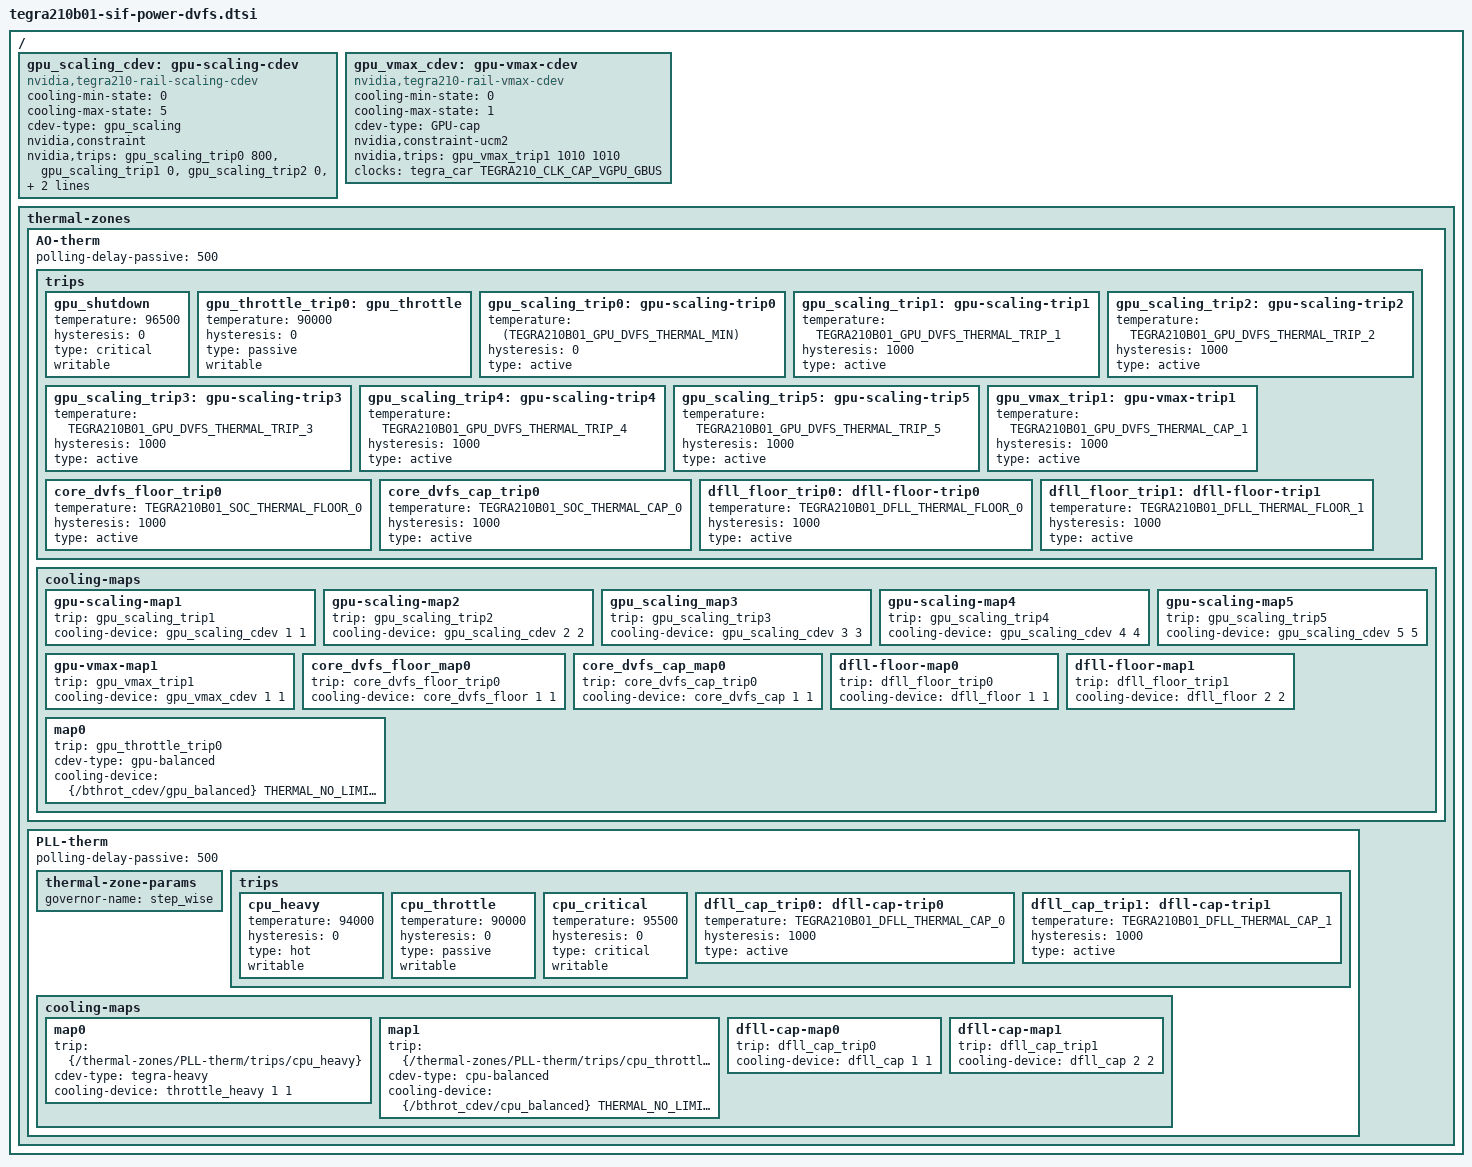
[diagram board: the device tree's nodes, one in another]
/*
 * Copyright (c) 2018, NVIDIA CORPORATION. All rights reserved.
 *
 * This software is licensed under the terms of the GNU General Public
 * License version 2, as published by the Free Software Foundation, and
 * may be copied, distributed, and modified under those terms.
 *
 * This program is distributed in the hope that it will be useful,
 * but WITHOUT ANY WARRANTY; without even the implied warranty of
 * MERCHANTABILITY or FITNESS FOR A PARTICULAR PURPOSE.  See the
 * GNU General Public License for more details.
 *
 */

#include <dt-bindings/thermal/tegra210b01-trips.h>

/ {
	gpu_scaling_cdev: gpu-scaling-cdev {
		cooling-min-state = <0>;
		cooling-max-state = <5>;
		#cooling-cells = <2>;
		compatible = "nvidia,tegra210-rail-scaling-cdev";
		cdev-type = "gpu_scaling";
		nvidia,constraint;
		nvidia,trips = <&gpu_scaling_trip0 800 &gpu_scaling_trip1 0
				&gpu_scaling_trip2 0 &gpu_scaling_trip3 0
				&gpu_scaling_trip4 0 &gpu_scaling_trip5 0>;
	};

	gpu_vmax_cdev: gpu-vmax-cdev {
		cooling-min-state = <0>;
		cooling-max-state = <1>;
		#cooling-cells = <2>;
		compatible = "nvidia,tegra210-rail-vmax-cdev";
		cdev-type = "GPU-cap";
		nvidia,constraint-ucm2;
		nvidia,trips = <&gpu_vmax_trip1 1010 1010>;
		clocks = <&tegra_car TEGRA210_CLK_CAP_VGPU_GBUS>;
		clock-names = "cap-clk";
	};

	thermal-zones {
		AO-therm {
			status = "okay";
			polling-delay-passive = <500>;
			trips {
				gpu_shutdown {
					temperature = <96500>;
					hysteresis = <0>;
					type = "critical";
					writable;
				};

				gpu_throttle_trip0: gpu_throttle {
					temperature = <90000>;
					hysteresis = <0>;
					type = "passive";
					writable;
				};

				gpu_scaling_trip0: gpu-scaling-trip0 {
					temperature = <(TEGRA210B01_GPU_DVFS_THERMAL_MIN)>;
					hysteresis = <0>; /* millicelsius */
					type = "active";
				};
				gpu_scaling_trip1: gpu-scaling-trip1 {
					temperature = <TEGRA210B01_GPU_DVFS_THERMAL_TRIP_1>;
					hysteresis = <1000>; /* millicelsius */
					type = "active";
				};
				gpu_scaling_trip2: gpu-scaling-trip2 {
					temperature = <TEGRA210B01_GPU_DVFS_THERMAL_TRIP_2>;
					hysteresis = <1000>; /* millicelsius */
					type = "active";
				};
				gpu_scaling_trip3: gpu-scaling-trip3 {
					temperature = <TEGRA210B01_GPU_DVFS_THERMAL_TRIP_3>;
					hysteresis = <1000>; /* millicelsius */
					type = "active";
				};
				gpu_scaling_trip4: gpu-scaling-trip4 {
					temperature = <TEGRA210B01_GPU_DVFS_THERMAL_TRIP_4>;
					hysteresis = <1000>; /* millicelsius */
					type = "active";
				};
				gpu_scaling_trip5: gpu-scaling-trip5 {
					temperature = <TEGRA210B01_GPU_DVFS_THERMAL_TRIP_5>;
					hysteresis = <1000>; /* millicelsius */
					type = "active";
				};

				gpu_vmax_trip1: gpu-vmax-trip1 {
					temperature = <TEGRA210B01_GPU_DVFS_THERMAL_CAP_1>;
					hysteresis = <1000>; /* millicelsius */
					type = "active";
				};

				core_dvfs_floor_trip0: core_dvfs_floor_trip0 {
					temperature = <TEGRA210B01_SOC_THERMAL_FLOOR_0>;
					hysteresis = <1000>;
					type = "active";
				};

				core_dvfs_cap_trip0: core_dvfs_cap_trip0 {
					temperature = <TEGRA210B01_SOC_THERMAL_CAP_0>;
					hysteresis = <1000>;
					type = "active";
				};

				dfll_floor_trip0: dfll-floor-trip0 {
					temperature = <TEGRA210B01_DFLL_THERMAL_FLOOR_0>;
					hysteresis = <1000>; /* millicelsius */
					type = "active";
				};
				dfll_floor_trip1: dfll-floor-trip1 {
					temperature = <TEGRA210B01_DFLL_THERMAL_FLOOR_1>;
					hysteresis = <1000>; /* millicelsius */
					type = "active";
				};
			};

			cooling-maps {
				gpu-scaling-map1 {
					trip = <&gpu_scaling_trip1>;
					cooling-device = <&gpu_scaling_cdev 1 1>;
				};
				gpu-scaling-map2 {
					trip = <&gpu_scaling_trip2>;
					cooling-device = <&gpu_scaling_cdev 2 2>;
				};
				gpu_scaling_map3 {
					trip = <&gpu_scaling_trip3>;
					cooling-device = <&gpu_scaling_cdev 3 3>;
				};
				gpu-scaling-map4 {
					trip = <&gpu_scaling_trip4>;
					cooling-device = <&gpu_scaling_cdev 4 4>;
				};
				gpu-scaling-map5 {
					trip = <&gpu_scaling_trip5>;
					cooling-device = <&gpu_scaling_cdev 5 5>;
				};

				gpu-vmax-map1 {
					trip = <&gpu_vmax_trip1>;
					cooling-device = <&gpu_vmax_cdev 1 1>;
				};

				core_dvfs_floor_map0 {
					trip = <&core_dvfs_floor_trip0>;
					cooling-device = <&core_dvfs_floor 1 1>;
				};
				core_dvfs_cap_map0 {
					trip = <&core_dvfs_cap_trip0>;
					cooling-device = <&core_dvfs_cap 1 1>;
				};

				dfll-floor-map0 {
					trip = <&dfll_floor_trip0>;
					cooling-device = <&dfll_floor 1 1>;
				};
				dfll-floor-map1 {
					trip = <&dfll_floor_trip1>;
					cooling-device = <&dfll_floor 2 2>;
				};
				map0 {
					trip = <&gpu_throttle_trip0>;
					cdev-type = "gpu-balanced";
					cooling-device = <&{/bthrot_cdev/gpu_balanced}
						THERMAL_NO_LIMIT THERMAL_NO_LIMIT>;
				};
			};
		};

		PLL-therm {
			status = "okay";
			polling-delay-passive = <500>;
			thermal-zone-params {
				governor-name = "step_wise";
			};
			trips {
				cpu_heavy {
					temperature = <94000>;
					hysteresis = <0>;
					type = "hot";
					writable;
				};
				cpu_throttle {
					temperature = <90000>;
					hysteresis = <0>;
					type = "passive";
					writable;
				};
				cpu_critical {
					temperature = <95500>;
					hysteresis = <0>;
					type = "critical";
					writable;
				};
				dfll_cap_trip0: dfll-cap-trip0 {
					temperature = <TEGRA210B01_DFLL_THERMAL_CAP_0>;
					hysteresis = <1000>; /* millicelsius */
					type = "active";
				};
				dfll_cap_trip1: dfll-cap-trip1 {
					temperature = <TEGRA210B01_DFLL_THERMAL_CAP_1>;
					hysteresis = <1000>; /* millicelsius */
					type = "active";
				};
			};
			cooling-maps {
				map0 {
					trip = <&{/thermal-zones/PLL-therm/trips/cpu_heavy}>;
					cdev-type = "tegra-heavy";
					cooling-device = <&throttle_heavy 1 1>;
				};
				map1 {
					trip = <&{/thermal-zones/PLL-therm/trips/cpu_throttle}>;
					cdev-type = "cpu-balanced";
					cooling-device = <&{/bthrot_cdev/cpu_balanced}
						THERMAL_NO_LIMIT THERMAL_NO_LIMIT>;
				};
				dfll-cap-map0 {
					trip = <&dfll_cap_trip0>;
					cooling-device = <&dfll_cap 1 1>;
				};
				dfll-cap-map1 {
					trip = <&dfll_cap_trip1>;
					cooling-device = <&dfll_cap 2 2>;
				};
			};
		};
	};
};

